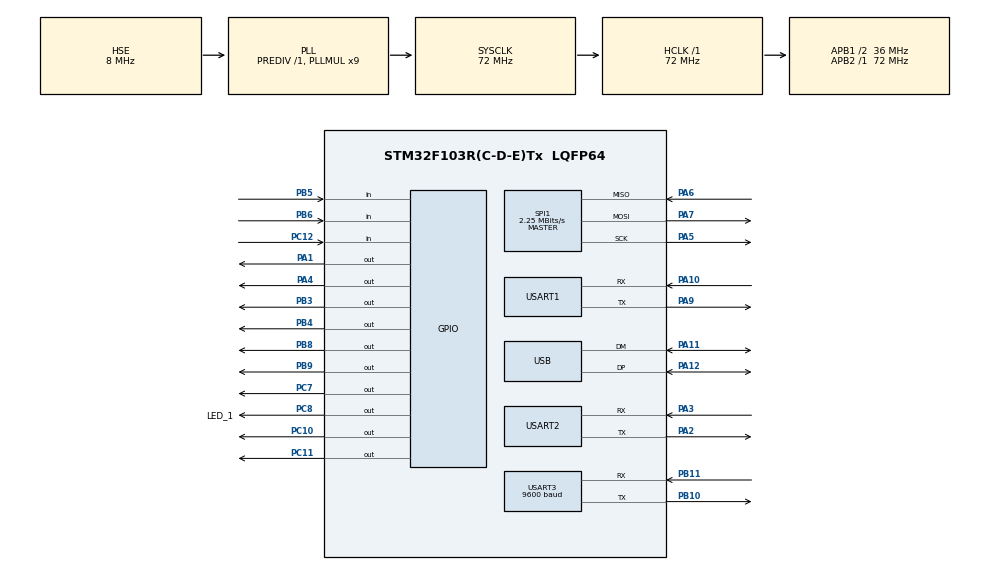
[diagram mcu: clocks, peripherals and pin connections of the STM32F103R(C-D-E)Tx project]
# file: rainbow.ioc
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Mcu.Family=STM32F1
Mcu.Name=STM32F103R(C-D-E)Tx
Mcu.Package=LQFP64
NVIC.PriorityGroup=NVIC_PRIORITYGROUP_2
NVIC.TIM2_IRQn=true\:2\:1\:true\:false\:true\:true\:true
NVIC.TIM6_IRQn=true\:2\:3\:true\:false\:true\:true\:true
NVIC.USART1_IRQn=true\:3\:3\:true\:false\:true\:true\:true
NVIC.USART2_IRQn=true\:3\:2\:true\:false\:true\:true\:true
NVIC.USART3_IRQn=true\:3\:1\:true\:false\:true\:true\:true
PA1.PinState=GPIO_PIN_RESET
PA1.Signal=GPIO_Output
PA10.GPIO_Mode=GPIO_MODE_INPUT
PA10.Mode=Asynchronous
PA10.Signal=USART1_RX
PA11.Mode=Device
PA11.Signal=USB_DM
PA12.Mode=Device
PA12.Signal=USB_DP
PA13.Mode=Serial_Wire
PA13.Signal=SYS_JTMS-SWDIO
PA14.Mode=Serial_Wire
PA14.Signal=SYS_JTCK-SWCLK
PA2.GPIO_Mode=GPIO_MODE_AF_PP
PA2.Mode=Asynchronous
PA2.Signal=USART2_TX
PA3.GPIO_Mode=GPIO_MODE_INPUT
PA3.Mode=Asynchronous
PA3.Signal=USART2_RX
PA4.GPIO_PuPd=GPIO_NOPULL
PA4.GPIO_Speed=GPIO_SPEED_FREQ_LOW
PA4.Signal=GPIO_Output
PA5.GPIO_Mode=GPIO_MODE_AF_PP
PA5.Mode=Full_Duplex_Master
PA5.Signal=SPI1_SCK
PA6.GPIO_Mode=GPIO_MODE_INPUT
PA6.Mode=Full_Duplex_Master
PA6.Signal=SPI1_MISO
PA7.GPIO_Mode=GPIO_MODE_AF_PP
PA7.Mode=Full_Duplex_Master
PA7.Signal=SPI1_MOSI
PA9.GPIO_Mode=GPIO_MODE_AF_PP
PA9.Mode=Asynchronous
PA9.Signal=USART1_TX
PB10.GPIO_Mode=GPIO_MODE_AF_PP
PB10.Mode=Asynchronous
PB10.Signal=USART3_TX
PB11.GPIO_Mode=GPIO_MODE_INPUT
PB11.Mode=Asynchronous
PB11.Signal=USART3_RX
PB3.GPIO_ModeDefaultOutputPP=GPIO_MODE_OUTPUT_PP
PB3.Signal=GPIO_Output
PB4.PinState=GPIO_PIN_RESET
PB4.Signal=GPIO_Output
PB5.GPIO_Mode=GPIO_MODE_INPUT
PB5.Signal=GPIO_Input
PB6.GPIO_Mode=GPIO_MODE_INPUT
PB6.Signal=GPIO_Input
PB8.PinState=GPIO_PIN_RESET
PB8.Signal=GPIO_Output
PB9.PinState=GPIO_PIN_RESET
PB9.Signal=GPIO_Output
PC10.PinState=GPIO_PIN_RESET
PC10.Signal=GPIO_Output
PC11.PinState=GPIO_PIN_RESET
PC11.Signal=GPIO_Output
PC12.GPIO_Mode=GPIO_MODE_INPUT
PC12.Signal=GPIO_Input
PC7.PinState=GPIO_PIN_RESET
PC7.Signal=GPIO_Output
PC8.GPIO_Label=LED_1
PC8.PinState=GPIO_PIN_RESET
PC8.Signal=GPIO_Output
PD0-OSC_IN.Mode=HSE-External-Oscillator
PD0-OSC_IN.Signal=RCC_OSC_IN
PD1-OSC_OUT.Mode=HSE-External-Oscillator
PD1-OSC_OUT.Signal=RCC_OSC_OUT
ProjectManager.HeapSize=0x400
ProjectManager.StackSize=0x800
ProjectManager.TargetToolchain=MDK-ARM V5
RCC.AHBFreq_Value=72000000
RCC.APB1CLKDivider=RCC_HCLK_DIV2
RCC.APB1Freq_Value=36000000
RCC.APB1TimFreq_Value=72000000
RCC.APB2Freq_Value=72000000
RCC.APB2TimFreq_Value=72000000
RCC.HCLKFreq_Value=72000000
RCC.PLLMUL=RCC_PLL_MUL9
RCC.SYSCLKFreq_VALUE=72000000
RCC.SYSCLKSource=RCC_SYSCLKSOURCE_PLLCLK
RCC.USBFreq_Value=48000000
RCC.USBPrescaler=RCC_USBCLKSOURCE_PLL_DIV1_5
SPI1.BaudRatePrescaler=SPI_BAUDRATEPRESCALER_32
SPI1.CalculateBaudRate=2.25 MBits/s
SPI1.Direction=SPI_DIRECTION_2LINES
SPI1.Mode=SPI_MODE_MASTER
SPI1.VirtualType=VM_MASTER
TIM2.AutoReloadPreload=TIM_AUTORELOAD_PRELOAD_DISABLE
TIM2.Period=10
TIM2.Prescaler=7199
TIM6.Period=900
TIM6.Prescaler=7199
USART1.VirtualMode=VM_ASYNC
USART2.VirtualMode=VM_ASYNC
USART3.BaudRate=9600
USART3.VirtualMode=VM_ASYNC
VP_TIM2_VS_ClockSourceINT.Mode=Internal
VP_TIM6_VS_ClockSourceINT.Mode=Enable_Timer
board=custom

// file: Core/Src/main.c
/* USER CODE BEGIN Header */
/**
  ******************************************************************************
  * @file           : main.c
  * @brief          : Main program body
  ******************************************************************************
  * @attention
  *
  * <h2><center>&copy; Copyright (c) 2019 STMicroelectronics.
  * All rights reserved.</center></h2>
  *
  * This software component is licensed by ST under BSD 3-Clause license,
  * the "License"; You may not use this file except in compliance with the
  * License. You may obtain a copy of the License at:
  *                        opensource.org/licenses/BSD-3-Clause
  *
  ******************************************************************************
  */
/* USER CODE END Header */

#include "main.h"
#include "spi.h"
#include "tim.h"
#include "usart.h"
#include "usb.h"
#include "gpio.h"

/* USER CODE BEGIN Includes */
#include "include.h"
/* USER CODE END Includes */

void SystemClock_Config(void);

int main(void)
{

    /* MCU Configuration--------------------------------------------------------*/

    /* Reset of all peripherals, Initializes the Flash interface and the Systick. */
    HAL_Init();

    /* USER CODE BEGIN Init */
    HAL_DeInit();

    /* USER CODE END Init */

    /* Configure the system clock */
//    SystemClock_Config();

    /* USER CODE BEGIN SysInit */
    LOS_KernelInit();

    creat_task();

    LOS_Start();
    /* USER CODE END SysInit */

    /* Initialize all configured peripherals */
    MX_GPIO_Init();
    MX_SPI1_Init();
    MX_TIM6_Init();
    MX_USART1_UART_Init();
    MX_USART2_UART_Init();
    MX_USART3_UART_Init();
    MX_USB_PCD_Init();
    MX_TIM2_Init();

    /* Infinite loop */
    while (1)
    {

    }
}

void SystemClock_Config(void)
{
    RCC_OscInitTypeDef RCC_OscInitStruct = {0};
    RCC_ClkInitTypeDef RCC_ClkInitStruct = {0};
    RCC_PeriphCLKInitTypeDef PeriphClkInit = {0};

    /** Initializes the CPU, AHB and APB busses clocks
    */
    RCC_OscInitStruct.OscillatorType = RCC_OSCILLATORTYPE_HSE;
    RCC_OscInitStruct.HSEState = RCC_HSE_ON;
    RCC_OscInitStruct.HSEPredivValue = RCC_HSE_PREDIV_DIV1;
    RCC_OscInitStruct.HSIState = RCC_HSI_ON;
    RCC_OscInitStruct.PLL.PLLState = RCC_PLL_ON;
    RCC_OscInitStruct.PLL.PLLSource = RCC_PLLSOURCE_HSE;
    RCC_OscInitStruct.PLL.PLLMUL = RCC_PLL_MUL9;
    if (HAL_RCC_OscConfig(&RCC_OscInitStruct) != HAL_OK)
    {
        Error_Handler();
    }
    /** Initializes the CPU, AHB and APB busses clocks
    */
    RCC_ClkInitStruct.ClockType = RCC_CLOCKTYPE_HCLK|RCC_CLOCKTYPE_SYSCLK
                                  |RCC_CLOCKTYPE_PCLK1|RCC_CLOCKTYPE_PCLK2;
    RCC_ClkInitStruct.SYSCLKSource = RCC_SYSCLKSOURCE_PLLCLK;
    RCC_ClkInitStruct.AHBCLKDivider = RCC_SYSCLK_DIV1;
    RCC_ClkInitStruct.APB1CLKDivider = RCC_HCLK_DIV2;
    RCC_ClkInitStruct.APB2CLKDivider = RCC_HCLK_DIV1;

    if (HAL_RCC_ClockConfig(&RCC_ClkInitStruct, FLASH_LATENCY_2) != HAL_OK)
    {
        Error_Handler();
    }
    PeriphClkInit.PeriphClockSelection = RCC_PERIPHCLK_USB;
    PeriphClkInit.UsbClockSelection = RCC_USBCLKSOURCE_PLL_DIV1_5;
    if (HAL_RCCEx_PeriphCLKConfig(&PeriphClkInit) != HAL_OK)
    {
        Error_Handler();
    }
}

void Error_Handler(void)
{
}

/************************ (C) COPYRIGHT STMicroelectronics *****END OF FILE****/
